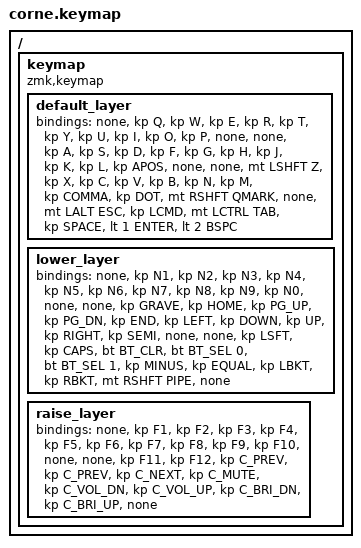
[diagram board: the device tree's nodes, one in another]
/*
 * Copyright (c) 2020 The ZMK Contributors
 *
 * SPDX-License-Identifier: MIT
 */



#include <behaviors.dtsi>
#include <dt-bindings/zmk/keys.h>
#include <dt-bindings/zmk/bt.h>

/ {
        keymap {
                compatible = "zmk,keymap";

                default_layer {
// -------------------------------------------------------------------------------------
// |   Q   |  W  |  E  |  R  |  T  |   |  Y  |  U   |  I  |  O  |  P      | 
// |   A   |  S  |  D  |  F  |  G  |   |  H  |  J   |  K  |  L  |  ' "    |
// | SHF/Z |  X  |  C  |  V  |  B  |   |  N  |  M   |  ,< |  .> | SHFT/?  |
//       | OPT/ESC | CMD | CTR/TAB |   | ENTER | L1/SPC | L2/BSP |
                        bindings = <
   &none        &kp Q           &kp W	        &kp E	        &kp R    	&kp T   	&kp Y           &kp U   &kp I        	&kp O           &kp P                &none
   &none        &kp A	        &kp S           &kp D   	&kp F   	&kp G   	&kp H   	&kp J   &kp K   	&kp L           &kp APOS             &none
   &none        &mt LSHFT Z     &kp X   	&kp C  		&kp V   	&kp B           &kp N   	&kp M   &kp COMMA       &kp DOT	        &mt RSHFT QMARK      &none
   &mt LALT ESC &kp LCMD        &mt LCTRL TAB   &kp SPACE       &lt 1 ENTER     &lt 2 BSPC
                                >;
                };

                lower_layer {
// ----------------------------------------------------------------------------------
// |  1! |  2@  |  3#  |  4$  |  5%  |   |  6^  |  7&  |  8*  |  9(  |  0) |
// | `~  | HOME | PGUP | PGDN | END  |   | LEFT | DOWN |  UP | RGHT |  ;:  | 
// | SHST| CAPS |      |      |      |   |  -_  |  =+  | [{  | ]}   | SHF\||
//              |      |      |      |   |      |(hold)|     |
                        bindings = <
&none   &kp N1       &kp N2      	&kp N3 		&kp N4 		&kp N5      	&kp N6 		&kp N7 		&kp N8          &kp N9  	&kp N0          &none
&none   &kp GRAVE   	&kp HOME  	&kp PG_UP 	&kp PG_DN 	&kp END       	&kp LEFT 	&kp DOWN 	&kp UP    	&kp RIGHT       &kp SEMI        &none
&none   &kp LSFT   	&kp CAPS    	&bt BT_CLR 	&bt BT_SEL 0 	&bt BT_SEL 1 	&kp MINUS 	&kp EQUAL       &kp LBKT        &kp RBKT        &mt RSHFT PIPE  &none
                        >;
               };

                raise_layer {
// -----------------------------------------------------------------------------------------
// |  F1  |  F2  |  F3  |  F4  |  F5  |   |  F6  |  F7  |  F8  |  F9  |  F10  | 
// |  F11 |  F12 | PREV | PLAY | NEXT |   | MUTE | Vol- | Vol+ | Br-  |  Br+  | 
// |      |      |      |      |      |   |      |      |      |      |       |   
//                      |      |      |   |      |      |(hold)| 
                        bindings = <
&none   &kp F1    	&kp F2          &kp F3    	&kp F4    	&kp F5        	&kp F6    	&kp F7    	&kp F8   	&kp F9          &kp F10         &none
&none   &kp F11  	&kp F12         &kp C_PREV  	&kp C_PREV  	&kp C_NEXT     	&kp C_MUTE    	&kp C_VOL_DN    &kp C_VOL_UP    &kp C_BRI_DN    &kp C_BRI_UP    &none
                             
                        >;
               };
        };
};
